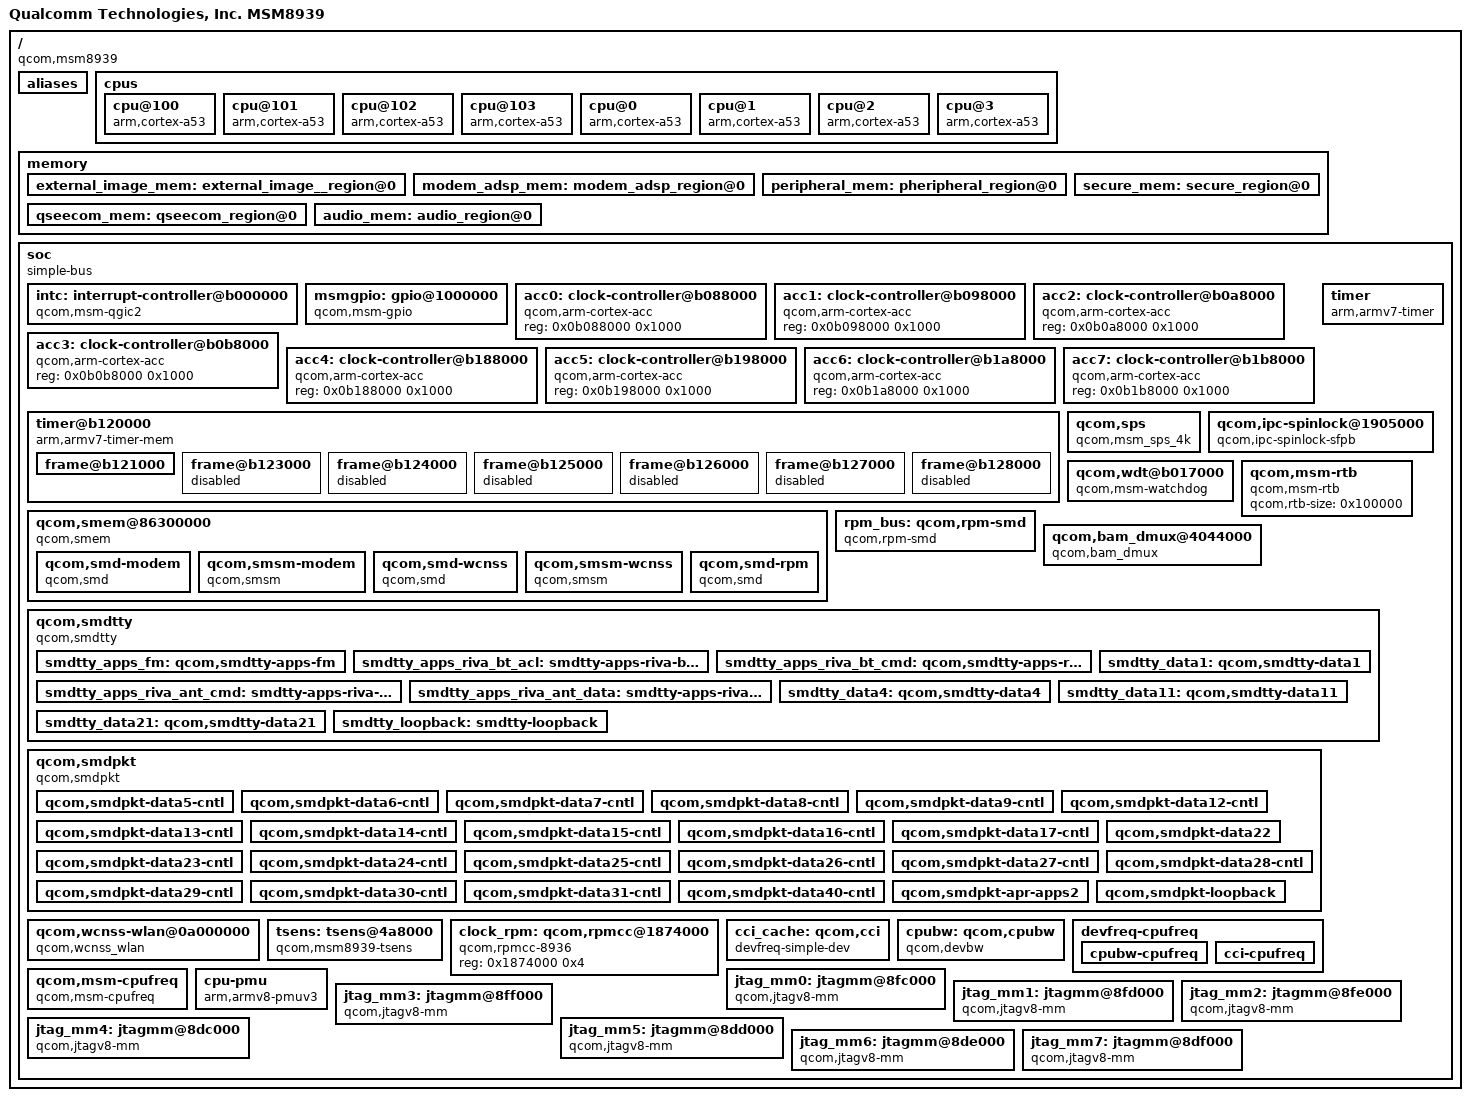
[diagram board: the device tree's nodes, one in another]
/* Copyright (c) 2014, The Linux Foundation. All rights reserved.
 *
 * This program is free software; you can redistribute it and/or modify
 * it under the terms of the GNU General Public License version 2 and
 * only version 2 as published by the Free Software Foundation.
 *
 * This program is distributed in the hope that it will be useful,
 * but WITHOUT ANY WARRANTY; without even the implied warranty of
 * MERCHANTABILITY or FITNESS FOR A PARTICULAR PURPOSE.  See the
 * GNU General Public License for more details.
 */

#include "skeleton64.dtsi"
#include <dt-bindings/clock/msm-clocks-8936.h>

/ {
	model = "Qualcomm Technologies, Inc. MSM8939";
	compatible = "qcom,msm8939";
	qcom,msm-id = <239 0>, <241 0>;
	interrupt-parent = <&intc>;
	aliases {
		sdhc1 = &sdhc_1; /* SDC1 eMMC slot */
		sdhc2 = &sdhc_2; /* SDC2 SD card slot */
		/* smdtty devices */
		smd1 = &smdtty_apps_fm;
		smd2 = &smdtty_apps_riva_bt_acl;
		smd3 = &smdtty_apps_riva_bt_cmd;
		smd5 = &smdtty_apps_riva_ant_cmd;
		smd6 = &smdtty_apps_riva_ant_data;
		smd7 = &smdtty_data1;
		smd8 = &smdtty_data4;
		smd11 = &smdtty_data11;
		smd21 = &smdtty_data21;
		smd36 = &smdtty_loopback;
		i2c0 = &i2c_0;
		spi0 = &spi_0;
	};

	cpus {
		#address-cells = <1>;
		#size-cells = <0>;
		cpu@100 {
			device_type = "cpu";
			compatible = "arm,cortex-a53";
			reg = <0x100>;
			enable-method = "qcom,arm-cortex-acc";
			qcom,acc = <&acc0>;
		};

		cpu@101 {
			device_type = "cpu";
			compatible = "arm,cortex-a53";
			reg = <0x101>;
			enable-method = "qcom,arm-cortex-acc";
			qcom,acc = <&acc1>;
		};

		cpu@102 {
			device_type = "cpu";
			compatible = "arm,cortex-a53";
			reg = <0x102>;
			enable-method = "qcom,arm-cortex-acc";
			qcom,acc = <&acc2>;
		};

		cpu@103 {
			device_type = "cpu";
			compatible = "arm,cortex-a53";
			reg = <0x103>;
			enable-method = "qcom,arm-cortex-acc";
			qcom,acc = <&acc3>;
		};

		cpu@0 {
			device_type = "cpu";
			compatible = "arm,cortex-a53";
			reg = <0x0>;
			enable-method = "qcom,arm-cortex-acc";
			qcom,acc = <&acc4>;
		};

		cpu@1 {
			device_type = "cpu";
			compatible = "arm,cortex-a53";
			reg = <0x1>;
			enable-method = "qcom,arm-cortex-acc";
			qcom,acc = <&acc5>;
		};

		cpu@2 {
			device_type = "cpu";
			compatible = "arm,cortex-a53";
			reg = <0x2>;
			enable-method = "qcom,arm-cortex-acc";
			qcom,acc = <&acc6>;
		};

		cpu@3 {
			device_type = "cpu";
			compatible = "arm,cortex-a53";
			reg = <0x3>;
			enable-method = "qcom,arm-cortex-acc";
			qcom,acc = <&acc7>;
		};
	};

	memory {
		#address-cells = <2>;
		#size-cells = <2>;

		external_image_mem: external_image__region@0 {
			linux,reserve-contiguous-region;
			linux,reserve-region;
			linux,remove-completely;
			reg = <0x0 0x8e200000 0x0 0x0800000>;
			label = "external_image_mem";
		};

		modem_adsp_mem: modem_adsp_region@0 {
			linux,reserve-contiguous-region;
			linux,reserve-region;
			linux,remove-completely;
			reg = <0x0 0x88800000 0x0 0x05a00000>;
			label = "modem_adsp_mem";
		};

		peripheral_mem: pheripheral_region@0 {
			linux,reserve-contiguous-region;
			linux,reserve-region;
			linux,remove-completely;
			reg = <0x0 0x8ea00000 0x0 0x0b00000>;
			label = "peripheral_mem";
		};

		secure_mem: secure_region@0 {
			linux,reserve-contiguous-region;
			reg = <0 0 0 0x6D00000>;
			label = "secure_mem";
		};

		qseecom_mem: qseecom_region@0 {
			linux,reserve-contiguous-region;
			reg = <0 0 0 0xd00000>;
			label = "qseecom_mem";
		};

		audio_mem: audio_region@0 {
			linux,reserve-contiguous-region;
			reg = <0 0 0 0x314000>;
			label = "audio_mem";
		};
	};

	soc: soc { };
};

#include "msm8939-smp2p.dtsi"
#include "msm8939-ipcrouter.dtsi"
#include "msm8939-ion.dtsi"
#include "msm-gdsc-8916.dtsi"
#include "msm8939-iommu.dtsi"
#include "msm8939-coresight.dtsi"
#include "msm8939-bus.dtsi"

&soc {
	#address-cells = <1>;
	#size-cells = <1>;
	ranges = <0 0 0 0xffffffff>;
	compatible = "simple-bus";

	intc: interrupt-controller@b000000 {
		compatible = "qcom,msm-qgic2";
		interrupt-controller;
		#interrupt-cells = <3>;
		reg = <0x0b000000 0x1000>,
		<0x0b002000 0x1000>;
	};

	msmgpio: gpio@1000000 {
		compatible = "qcom,msm-gpio";
		gpio-controller;
		#gpio-cells = <2>;
		interrupt-controller;
		#interrupt-cells = <2>;
		reg = <0x1000000 0x300000>;
		ngpio = <122>;
		interrupts = <0 208 0>;
		qcom,direct-connect-irqs = <29>;
	};

	acc0:clock-controller@b088000 {
		compatible = "qcom,arm-cortex-acc";
		reg = <0x0b088000 0x1000>;
	};

	acc1:clock-controller@b098000 {
		compatible = "qcom,arm-cortex-acc";
		reg = <0x0b098000 0x1000>;
	};

	acc2:clock-controller@b0a8000 {
		compatible = "qcom,arm-cortex-acc";
		reg = <0x0b0a8000 0x1000>;
	};

	acc3:clock-controller@b0b8000 {
		compatible = "qcom,arm-cortex-acc";
		reg = <0x0b0b8000 0x1000>;
	};

	acc4:clock-controller@b188000 {
		compatible = "qcom,arm-cortex-acc";
		reg = <0x0b188000 0x1000>;
	};

	acc5:clock-controller@b198000 {
		compatible = "qcom,arm-cortex-acc";
		reg = <0x0b198000 0x1000>;
	};

	acc6:clock-controller@b1a8000 {
		compatible = "qcom,arm-cortex-acc";
		reg = <0x0b1a8000 0x1000>;
	};

	acc7:clock-controller@b1b8000 {
		compatible = "qcom,arm-cortex-acc";
		reg = <0x0b1b8000 0x1000>;
	};

	timer {
		compatible = "arm,armv7-timer";
		interrupts = <1 2 0xf08>,
			     <1 3 0xf08>,
			     <1 4 0xf08>,
			     <1 1 0xf08>;
		clock-frequency = <19200000>;
	};

	timer@b120000 {
		#address-cells = <1>;
		#size-cells = <1>;
		ranges;
		compatible = "arm,armv7-timer-mem";
		reg = <0xb120000 0x1000>;
		clock-frequency = <19200000>;

		frame@b121000 {
			frame-number = <0>;
			interrupts = <0 8 0x4>,
				     <0 7 0x4>;
			reg = <0xb121000 0x1000>,
			      <0xb122000 0x1000>;
		};

		frame@b123000 {
			frame-number = <1>;
			interrupts = <0 9 0x4>;
			reg = <0xb123000 0x1000>;
			status = "disabled";
		};

		frame@b124000 {
			frame-number = <2>;
			interrupts = <0 10 0x4>;
			reg = <0xb124000 0x1000>;
			status = "disabled";
		};

		frame@b125000 {
			frame-number = <3>;
			interrupts = <0 11 0x4>;
			reg = <0xb125000 0x1000>;
			status = "disabled";
		};

		frame@b126000 {
			frame-number = <4>;
			interrupts = <0 12 0x4>;
			reg = <0xb126000 0x1000>;
			status = "disabled";
		};

		frame@b127000 {
			frame-number = <5>;
			interrupts = <0 13 0x4>;
			reg = <0xb127000 0x1000>;
			status = "disabled";
		};

		frame@b128000 {
			frame-number = <6>;
			interrupts = <0 14 0x4>;
			reg = <0xb128000 0x1000>;
			status = "disabled";
		};
	};

	qcom,sps {
		compatible = "qcom,msm_sps_4k";
		qcom,device-type = <3>;
		qcom,pipe-attr-ee;
	};

	qcom,ipc-spinlock@1905000 {
		compatible = "qcom,ipc-spinlock-sfpb";
		reg = <0x1905000 0x8000>;
		qcom,num-locks = <8>;
	};

	qcom,wdt@b017000 {
		compatible = "qcom,msm-watchdog";
		reg = <0xb017000 0x1000>;
		reg-names = "wdt-base";
		interrupts = <0 3 0>, <0 4 0>;
		qcom,bark-time = <11000>;
		qcom,pet-time = <10000>;
		qcom,ipi-ping;
	};

	qcom,msm-rtb {
		compatible = "qcom,msm-rtb";
		qcom,rtb-size = <0x100000>;
	};

	qcom,smem@86300000 {
		compatible = "qcom,smem";
		reg = <0x86300000 0x100000>,
			<0x0b111008 0x4>,
			<0x60000 0x8000>,
			<0x193D000 0x8>;
		reg-names = "smem", "irq-reg-base", "aux-mem1", "smem_targ_info_reg";
		qcom,mpu-enabled;

		qcom,smd-modem {
			compatible = "qcom,smd";
			qcom,smd-edge = <0>;
			qcom,smd-irq-offset = <0x0>;
			qcom,smd-irq-bitmask = <0x1000>;
			interrupts = <0 25 1>;
			label = "modem";
		};

		qcom,smsm-modem {
			compatible = "qcom,smsm";
			qcom,smsm-edge = <0>;
			qcom,smsm-irq-offset = <0x0>;
			qcom,smsm-irq-bitmask = <0x2000>;
			interrupts = <0 26 1>;
		};

		qcom,smd-wcnss {
			compatible = "qcom,smd";
			qcom,smd-edge = <6>;
			qcom,smd-irq-offset = <0x0>;
			qcom,smd-irq-bitmask = <0x20000>;
			interrupts = <0 142 1>;
			label = "wcnss";
		};

		qcom,smsm-wcnss {
			compatible = "qcom,smsm";
			qcom,smsm-edge = <6>;
			qcom,smsm-irq-offset = <0x0>;
			qcom,smsm-irq-bitmask = <0x80000>;
			interrupts = <0 144 1>;
		};

		qcom,smd-rpm {
			compatible = "qcom,smd";
			qcom,smd-edge = <15>;
			qcom,smd-irq-offset = <0x0>;
			qcom,smd-irq-bitmask = <0x1>;
			interrupts = <0 168 1>;
			label = "rpm";
			qcom,irq-no-suspend;
			qcom,not-loadable;
		};
	};

        rpm_bus: qcom,rpm-smd {
                compatible = "qcom,rpm-smd";
                rpm-channel-name = "rpm_requests";
                rpm-channel-type = <15>; /* SMD_APPS_RPM */
		rpm-standalone; /* TODO: remove this after bring up */
        };

	qcom,bam_dmux@4044000 {
		compatible = "qcom,bam_dmux";
		reg = <0x4044000 0x19000>;
		interrupts = <0 29 1>;
		qcom,rx-ring-size = <32>;
	};

	qcom,smdtty {
		compatible = "qcom,smdtty";

		smdtty_apps_fm: qcom,smdtty-apps-fm {
			qcom,smdtty-remote = "wcnss";
			qcom,smdtty-port-name = "APPS_FM";
		};

		smdtty_apps_riva_bt_acl: smdtty-apps-riva-bt-acl {
			qcom,smdtty-remote = "wcnss";
			qcom,smdtty-port-name = "APPS_RIVA_BT_ACL";
		};

		smdtty_apps_riva_bt_cmd: qcom,smdtty-apps-riva-bt-cmd {
			qcom,smdtty-remote = "wcnss";
			qcom,smdtty-port-name = "APPS_RIVA_BT_CMD";
		};

		smdtty_apps_riva_ant_cmd: smdtty-apps-riva-ant-cmd {
			qcom,smdtty-remote = "wcnss";
			qcom,smdtty-port-name = "APPS_RIVA_ANT_CMD";
		};

		smdtty_apps_riva_ant_data: smdtty-apps-riva-ant-data {
			qcom,smdtty-remote = "wcnss";
			qcom,smdtty-port-name = "APPS_RIVA_ANT_DATA";
		};

		smdtty_data1: qcom,smdtty-data1 {
			qcom,smdtty-remote = "modem";
			qcom,smdtty-port-name = "DATA1";
		};

		smdtty_data4: qcom,smdtty-data4 {
			qcom,smdtty-remote = "modem";
			qcom,smdtty-port-name = "DATA4";
		};

		smdtty_data11: qcom,smdtty-data11 {
			qcom,smdtty-remote = "modem";
			qcom,smdtty-port-name = "DATA11";
		};

		smdtty_data21: qcom,smdtty-data21 {
			qcom,smdtty-remote = "modem";
			qcom,smdtty-port-name = "DATA21";
		};

		smdtty_loopback: smdtty-loopback {
			qcom,smdtty-remote = "modem";
			qcom,smdtty-port-name = "LOOPBACK";
			qcom,smdtty-dev-name = "LOOPBACK_TTY";
		};
	};

	qcom,smdpkt {
		compatible = "qcom,smdpkt";

		qcom,smdpkt-data5-cntl {
			qcom,smdpkt-remote = "modem";
			qcom,smdpkt-port-name = "DATA5_CNTL";
			qcom,smdpkt-dev-name = "smdcntl0";
		};

		qcom,smdpkt-data6-cntl {
			qcom,smdpkt-remote = "modem";
			qcom,smdpkt-port-name = "DATA6_CNTL";
			qcom,smdpkt-dev-name = "smdcntl1";
		};

		qcom,smdpkt-data7-cntl {
			qcom,smdpkt-remote = "modem";
			qcom,smdpkt-port-name = "DATA7_CNTL";
			qcom,smdpkt-dev-name = "smdcntl2";
		};

		qcom,smdpkt-data8-cntl {
			qcom,smdpkt-remote = "modem";
			qcom,smdpkt-port-name = "DATA8_CNTL";
			qcom,smdpkt-dev-name = "smdcntl3";
		};

		qcom,smdpkt-data9-cntl {
			qcom,smdpkt-remote = "modem";
			qcom,smdpkt-port-name = "DATA9_CNTL";
			qcom,smdpkt-dev-name = "smdcntl4";
		};

		qcom,smdpkt-data12-cntl {
			qcom,smdpkt-remote = "modem";
			qcom,smdpkt-port-name = "DATA12_CNTL";
			qcom,smdpkt-dev-name = "smdcntl5";
		};

		qcom,smdpkt-data13-cntl {
			qcom,smdpkt-remote = "modem";
			qcom,smdpkt-port-name = "DATA13_CNTL";
			qcom,smdpkt-dev-name = "smdcntl6";
		};

		qcom,smdpkt-data14-cntl {
			qcom,smdpkt-remote = "modem";
			qcom,smdpkt-port-name = "DATA14_CNTL";
			qcom,smdpkt-dev-name = "smdcntl7";
		};

		qcom,smdpkt-data15-cntl {
			qcom,smdpkt-remote = "modem";
			qcom,smdpkt-port-name = "DATA15_CNTL";
			qcom,smdpkt-dev-name = "smdcntl9";
		};

		qcom,smdpkt-data16-cntl {
			qcom,smdpkt-remote = "modem";
			qcom,smdpkt-port-name = "DATA16_CNTL";
			qcom,smdpkt-dev-name = "smdcntl10";
		};

		qcom,smdpkt-data17-cntl {
			qcom,smdpkt-remote = "modem";
			qcom,smdpkt-port-name = "DATA17_CNTL";
			qcom,smdpkt-dev-name = "smdcntl11";
		};

		qcom,smdpkt-data22 {
			qcom,smdpkt-remote = "modem";
			qcom,smdpkt-port-name = "DATA22";
			qcom,smdpkt-dev-name = "smd22";
		};

		qcom,smdpkt-data23-cntl {
			qcom,smdpkt-remote = "modem";
			qcom,smdpkt-port-name = "DATA23_CNTL";
			qcom,smdpkt-dev-name = "smdcnt_rev0";
		};

		qcom,smdpkt-data24-cntl {
			qcom,smdpkt-remote = "modem";
			qcom,smdpkt-port-name = "DATA24_CNTL";
			qcom,smdpkt-dev-name = "smdcnt_rev1";
		};

		qcom,smdpkt-data25-cntl {
			qcom,smdpkt-remote = "modem";
			qcom,smdpkt-port-name = "DATA25_CNTL";
			qcom,smdpkt-dev-name = "smdcnt_rev2";
		};

		qcom,smdpkt-data26-cntl {
			qcom,smdpkt-remote = "modem";
			qcom,smdpkt-port-name = "DATA26_CNTL";
			qcom,smdpkt-dev-name = "smdcnt_rev3";
		};

		qcom,smdpkt-data27-cntl {
			qcom,smdpkt-remote = "modem";
			qcom,smdpkt-port-name = "DATA27_CNTL";
			qcom,smdpkt-dev-name = "smdcnt_rev4";
		};

		qcom,smdpkt-data28-cntl {
			qcom,smdpkt-remote = "modem";
			qcom,smdpkt-port-name = "DATA28_CNTL";
			qcom,smdpkt-dev-name = "smdcnt_rev5";
		};

		qcom,smdpkt-data29-cntl {
			qcom,smdpkt-remote = "modem";
			qcom,smdpkt-port-name = "DATA29_CNTL";
			qcom,smdpkt-dev-name = "smdcnt_rev6";
		};

		qcom,smdpkt-data30-cntl {
			qcom,smdpkt-remote = "modem";
			qcom,smdpkt-port-name = "DATA30_CNTL";
			qcom,smdpkt-dev-name = "smdcnt_rev7";
		};

		qcom,smdpkt-data31-cntl {
			qcom,smdpkt-remote = "modem";
			qcom,smdpkt-port-name = "DATA31_CNTL";
			qcom,smdpkt-dev-name = "smdcnt_rev8";
		};

		qcom,smdpkt-data40-cntl {
			qcom,smdpkt-remote = "modem";
			qcom,smdpkt-port-name = "DATA40_CNTL";
			qcom,smdpkt-dev-name = "smdcntl8";
		};

		qcom,smdpkt-apr-apps2 {
			qcom,smdpkt-remote = "modem";
			qcom,smdpkt-port-name = "apr_apps2";
			qcom,smdpkt-dev-name = "apr_apps2";
		};

		qcom,smdpkt-loopback {
			qcom,smdpkt-remote = "modem";
			qcom,smdpkt-port-name = "LOOPBACK";
			qcom,smdpkt-dev-name = "smd_pkt_loopback";
		};
	};

	qcom,wcnss-wlan@0a000000 {
		compatible = "qcom,wcnss_wlan";
		reg = <0x0a000000 0x280000>,
			<0xb011008 0x04>,
			<0x0a21b000 0x3000>,
			<0x03204000 0x00000100>,
			<0x03200800 0x00000200>,
			<0x0A100400 0x00000200>,
			<0x0A205050 0x00000200>,
			<0x0A219000 0x00000020>,
			<0x0A080488 0x00000008>,
			<0x0A080fb0 0x00000008>,
			<0x0A08040c 0x00000008>,
			<0x0A0120a8 0x00000008>,
			<0x0A012448 0x00000008>,
			<0x0A080c00 0x00000001>;

		reg-names = "wcnss_mmio", "wcnss_fiq",
			    "pronto_phy_base", "riva_phy_base",
			    "riva_ccu_base", "pronto_a2xb_base",
			    "pronto_ccpu_base", "pronto_saw2_base",
			    "wlan_tx_phy_aborts","wlan_brdg_err_source",
			    "wlan_tx_status", "alarms_txctl",
			    "alarms_tactl", "pronto_mcu_base";

		interrupts = <0 145 0 0 146 0>;
		interrupt-names = "wcnss_wlantx_irq", "wcnss_wlanrx_irq";

		qcom,pronto-vddmx-supply = <&pm8916_l3>;
		qcom,pronto-vddcx-supply = <&pm8916_s1_corner>;
		qcom,pronto-vddpx-supply = <&pm8916_l7>;
		qcom,iris-vddxo-supply   = <&pm8916_l7>;
		qcom,iris-vddrfa-supply  = <&pm8916_s3>;
		qcom,iris-vddpa-supply   = <&pm8916_l9>;
		qcom,iris-vdddig-supply  = <&pm8916_l5>;

		pinctrl-names = "wcnss_default", "wcnss_sleep",
						"wcnss_gpio_default";
		pinctrl-0 = <&wcnss_default>;
		pinctrl-1 = <&wcnss_sleep>;
		pinctrl-2 = <&wcnss_gpio_default>;
		wcnss-gpio-base = <&msm_gpio 40 0>;

		clocks = <&clock_rpm clk_xo_wlan_clk>,
			 <&clock_rpm clk_rf_clk2>,
			 <&clock_gcc clk_wcnss_m_clk>;
		clock-names = "xo", "rf_clk", "wcnss_debug";

		qcom,has-autodetect-xo;
		qcom,is-pronto-vt;
		qcom,has-pronto-hw;
		qcom,wcnss-adc_tm = <&pm8916_adc_tm>;
	};

	tsens: tsens@4a8000 {
		compatible = "qcom,msm8939-tsens";
		reg = <0x4a8000 0x2000>,
		      <0x5c000  0x1000>;
		reg-names = "tsens_physical", "tsens_eeprom_physical";
		interrupts = <0 184 0>;
		qcom,sensors = <9>;
		qcom,slope = <3200 3200 3200 3200 3200 3200 3200 3200 3200>;
		qcom,sensor-id = <0 1 2 3 5 6 7 8 9>;
	};

	clock_rpm: qcom,rpmcc@1874000 {
		compatible = "qcom,rpmcc-8936";
		reg = <0x1874000 0x4>;
		reg-names = "cc_base";
		#clock-cells = <1>;

	};

	cci_cache: qcom,cci {
		compatible = "devfreq-simple-dev";
		clock-names = "devfreq_clk";
		clocks = <&clock_cpu clk_a53ssmux_cci>;
		governor = "cpufreq";
		freq-tbl-khz =
			<  200000 >,
			<  297600 >,
			<  400000 >,
			<  595200 >;
	};

	cpubw: qcom,cpubw {
		compatible = "qcom,devbw";
		governor = "cpufreq";
		qcom,src-dst-ports = <1 512>;
		qcom,active-only;
		qcom,bw-tbl =
			<  762  /*  100   MHz */ >,
			<  1525 /*  200   MHz */ >,
			<  1977 /*  259.2 MHz */ >,
			<  2545 /*  333.6 MHz */ >,
			<  3051 /*  400   MHz */ >;
	};

	devfreq-cpufreq {
		cpubw-cpufreq {
		target-dev = <&cpubw>;
		cpu-to-dev-map-0 =
			<  200000   762 >,
			<  345600  1525 >,
			<  400000  1977 >,
			<  422400  2545 >,
			<  499200  2545 >,
			<  533330  2545 >,
			<  652800  2545 >,
			<  729600  2545 >,
			<  800000  2545 >,
			<  806400  2545 >,
			<  883200  2545 >,
			<  960000  2545 >,
			<  1036800 3051 >,
			<  1113600 3051 >,
			<  1190400 3051 >,
			<  1267200 3051 >,
			<  1344000 3051 >,
			<  1420800 3051 >,
			<  1497600 3051 >,
			<  1536000 3051 >;
		cpu-to-dev-map-4 =
			<  200000  762 >,
			<  249600 1525 >,
			<  400000 2545 >,
			<  499200 2545 >,
			<  533330 3051 >,
			<  800000 3051 >,
			<  998400 3051 >;
		};

		cci-cpufreq {
		target-dev = <&cci_cache>;
		cpu-to-dev-map-0 =
			<  200000  200000 >,
			<  345600  200000 >,
			<  400000  200000 >,
			<  422400  200000 >,
			<  499200  200000 >,
			<  533330  297600 >,
			<  652800  297600 >,
			<  729600  297600 >,
			<  800000  297600 >,
			<  806400  297600 >,
			<  883200  297600 >,
			<  960000  400000 >,
			< 1036800  400000 >,
			< 1113600  400000 >,
			< 1190400  595200 >,
			< 1267200  595200 >,
			< 1344000  595200 >,
			< 1420800  595200 >,
			< 1497600  595200 >,
			< 1536000  595200 >;
		cpu-to-dev-map-4 =
			<  200000 200000 >,
			<  249600 200000 >,
			<  400000 297600 >,
			<  499200 297600 >,
			<  533330 400000 >,
			<  800000 400000 >,
			<  998400 400000 >;
		};
	};

	qcom,msm-cpufreq {
		compatible = "qcom,msm-cpufreq";
		clock-names = "cpu0_clk", "cpu1_clk", "cpu2_clk",
				"cpu3_clk", "cpu4_clk", "cpu5_clk",
				"cpu6_clk", "cpu7_clk";
		clocks = <&clock_cpu clk_a53ssmux_bc>,
			 <&clock_cpu clk_a53ssmux_bc>,
			 <&clock_cpu clk_a53ssmux_bc>,
			 <&clock_cpu clk_a53ssmux_bc>,
			 <&clock_cpu clk_a53ssmux_lc>,
			 <&clock_cpu clk_a53ssmux_lc>,
			 <&clock_cpu clk_a53ssmux_lc>,
			 <&clock_cpu clk_a53ssmux_lc>;

		qcom,governor-per-policy;

		qcom,cpufreq-table-0 =
			 <  200000 >,
			 <  345600 >,
			 <  400000 >,
			 <  422400 >,
			 <  499200 >,
			 <  533330 >,
			 <  652800 >,
			 <  729600 >,
			 <  800000 >,
			 <  806400 >,
			 <  883200 >,
                         <  960000 >,
			 < 1036800 >,
			 < 1113600 >,
			 < 1190400 >,
			 < 1267200 >,
			 < 1344000 >,
			 < 1420800 >,
			 < 1497600 >,
			 < 1536000 >;
		qcom,cpufreq-table-4 =
			 <  200000 >,
			 <  249600 >,
			 <  400000 >,
			 <  499200 >,
			 <  533330 >,
			 <  800000 >,
			 <  998400 >;
	};

	cpu-pmu {
		compatible = "arm,armv8-pmuv3";
		qcom,irq-is-percpu;
		interrupts = <1 7 0xff00>;
	};

	jtag_mm0: jtagmm@8fc000 {
		compatible = "qcom,jtagv8-mm";
		reg = <0x8fc000 0x1000>,
		      <0x8f0000 0x1000>;
		reg-names = "etm-base", "debug-base";

		clocks = <&clock_rpm clk_qdss_clk>,
		         <&clock_rpm clk_qdss_a_clk>;
		clock-names = "core_clk", "core_a_clk";

		qcom,coresight-jtagmm-cpu = <&CPU0>;
	};

	jtag_mm1: jtagmm@8fd000 {
		compatible = "qcom,jtagv8-mm";
		reg = <0x8fd000 0x1000>,
		      <0x8f2000 0x1000>;
		reg-names = "etm-base", "debug-base";

		clocks = <&clock_rpm clk_qdss_clk>,
		         <&clock_rpm clk_qdss_a_clk>;
		clock-names = "core_clk", "core_a_clk";

		qcom,coresight-jtagmm-cpu = <&CPU1>;
	};

	jtag_mm2: jtagmm@8fe000 {
		compatible = "qcom,jtagv8-mm";
		reg = <0x8fe000 0x1000>,
		      <0x8f4000 0x1000>;
		reg-names = "etm-base", "debug-base";

		clocks = <&clock_rpm clk_qdss_clk>,
		         <&clock_rpm clk_qdss_a_clk>;
		clock-names = "core_clk", "core_a_clk";

		qcom,coresight-jtagmm-cpu = <&CPU2>;
	};

	jtag_mm3: jtagmm@8ff000 {
		compatible = "qcom,jtagv8-mm";
		reg = <0x8ff000 0x1000>,
		      <0x8f6000 0x1000>;
		reg-names = "etm-base", "debug-base";

		clocks = <&clock_rpm clk_qdss_clk>,
		         <&clock_rpm clk_qdss_a_clk>;
		clock-names = "core_clk", "core_a_clk";

		qcom,coresight-jtagmm-cpu = <&CPU3>;
	};

	jtag_mm4: jtagmm@8dc000 {
		compatible = "qcom,jtagv8-mm";
		reg = <0x8dc000 0x1000>,
		      <0x8d0000 0x1000>;
		reg-names = "etm-base", "debug-base";

		clocks = <&clock_rpm clk_qdss_clk>,
		         <&clock_rpm clk_qdss_a_clk>;
		clock-names = "core_clk", "core_a_clk";

		qcom,coresight-jtagmm-cpu = <&CPU4>;
	};

	jtag_mm5: jtagmm@8dd000 {
		compatible = "qcom,jtagv8-mm";
		reg = <0x8dd000 0x1000>,
		      <0x8d2000 0x1000>;
		reg-names = "etm-base", "debug-base";

		clocks = <&clock_rpm clk_qdss_clk>,
		         <&clock_rpm clk_qdss_a_clk>;
		clock-names = "core_clk", "core_a_clk";

		qcom,coresight-jtagmm-cpu = <&CPU5>;
	};

	jtag_mm6: jtagmm@8de000 {
		compatible = "qcom,jtagv8-mm";
		reg = <0x8de000 0x1000>,
		      <0x8d4000 0x1000>;
		reg-names = "etm-base", "debug-base";

		clocks = <&clock_rpm clk_qdss_clk>,
		         <&clock_rpm clk_qdss_a_clk>;
		clock-names = "core_clk", "core_a_clk";

		qcom,coresight-jtagmm-cpu = <&CPU6>;
	};

	jtag_mm7: jtagmm@8df000 {
		compatible = "qcom,jtagv8-mm";
		reg = <0x8df000 0x1000>,
		      <0x8d6000 0x1000>;
		reg-names = "etm-base", "debug-base";

		clocks = <&clock_rpm clk_qdss_clk>,
		         <&clock_rpm clk_qdss_a_clk>;
		clock-names = "core_clk", "core_a_clk";

		qcom,coresight-jtagmm-cpu = <&CPU7>;
	};
};
